# LPC18xx register map
File version: 18
Registers are 32-bit, read-write, reset 0x0 unless marked. A register's access mark holds for its fields unless they carry their own. Offsets are from the block's base; [hi:lo] are bit positions; {n}, {i} and the like mark numbered series; 'fields as' and 'values as' point back to an identical list.

## LCD — Product name title=UM10430 Chapter title=LPC18xx LCD Modification date=1/19/2011 Major revision=0 Minor revision=7
Base 0x40008000
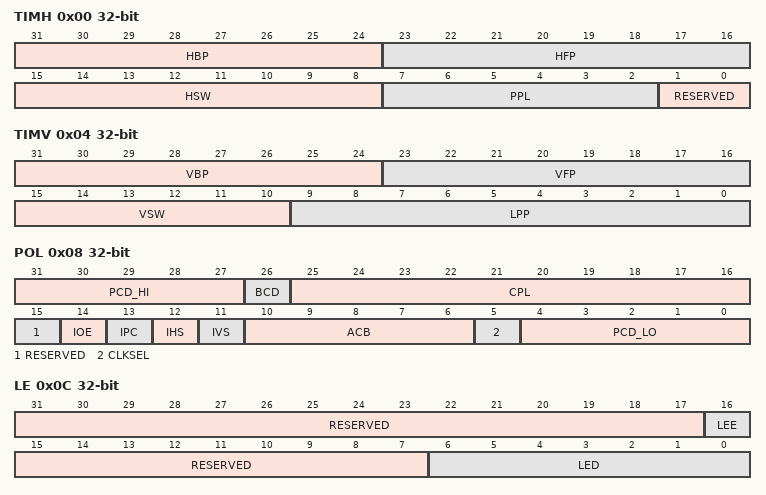
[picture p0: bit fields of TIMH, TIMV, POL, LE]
0x00 TIMH — Horizontal Timing Control register
  [31:24] HBP — Horizontal back porch. The 8-bit HBP field is used to specify the number of pixel clock periods inserted at the beginning of each line or row of pixels. After the line clock for the previous line has been deasserted, the value in HBP counts the number of pixel clocks to wait before starting the next display line. HBP can generate a delay of 1-256 pixel clock cycles. Program with desired value minus 1.
  [23:16] HFP — Horizontal front porch. The 8-bit HFP field sets the number of pixel clock intervals at the end of each line or row of pixels, before the LCD line clock is pulsed. When a complete line of pixels is transmitted to the LCD driver, the value in HFP counts the number of pixel clocks to wait before asserting the line clock. HFP can generate a period of 1-256 pixel clock cycles. Program with desired value minus 1.
  [15:8] HSW — Horizontal synchronization pulse width. The 8-bit HSW field specifies the pulse width of the line clock in passive mode, or the horizontal synchronization pulse in active mode. Program with desired value minus 1.
  [7:2] PPL — Pixels-per-line. The PPL bit field specifies the number of pixels in each line or row of the screen. PPL is a 6-bit value that represents between 16 and 1024 pixels per line. PPL counts the number of pixel clocks that occur before the HFP is applied. Program the value required divided by 16, minus 1. Actual pixels-per-line = 16 * (PPL + 1). For example, to obtain 320 pixels per line, program PPL as (320/16) -1 = 19.
  [1:0] RESERVED — Reserved, user software should not write ones to reserved bits. The value read from a reserved bit is not defined.
0x04 TIMV — Vertical Timing Control register
  [31:24] VBP — Vertical back porch. This is the number of inactive lines at the start of a frame, after the vertical synchronization period. The 8 bit VBP field specifies the number of line clocks inserted at the beginning of each frame. The VBP count starts immediately after the vertical synchronization signal for the previous frame has been negated for active mode, or the extra line clocks have been inserted as specified by the VSW bit field in passive mode. After this has occurred, the count value in VBP sets the number of line clock periods inserted before the next frame. VBP generates 0-255 extra line clock cycles. Program to zero on passive displays for improved contrast.
  [23:16] VFP — Vertical front porch. This is the number of inactive lines at the end of a frame, before the vertical synchronization period. The 8 bit VFP field specifies the number of line clocks to insert at the end of each frame. When a complete frame of pixels is transmitted to the LCD display, the value in VFP is used to count the number of line clock periods to wait. After the count has elapsed, the vertical synchronization signal, LCDFP, is asserted in active mode, or extra line clocks are inserted as specified by the VSW bit field in passive mode. VFP generates 0-255 line clock cycles. Program to zero on passive displays for improved contrast.
  [15:10] VSW — Vertical synchronization pulse width. This is the number of horizontal synchronization lines. The 6 bit VSW field specifies the pulse width of the vertical synchronization pulse. Program the register with the number of lines required, minus one. The number of horizontal synchronization lines must be small (for example, program to zero) for passive STN LCDs. The higher the value the worse the contrast on STN LCDs.
  [9:0] LPP — Lines per panel. This is the number of active lines per screen. The LPP field specifies the total number of lines or rows on the LCD panel being controlled. LPP is a 10 bit value allowing between 1 and 1024 lines. Program the register with the number of lines per LCD panel, minus 1. For dual panel displays, program the register with the number of lines on each of the upper and lower panels.
0x08 POL — Clock and Signal Polarity Control register
  [31:27] PCD_HI — Upper five bits of panel clock divisor. See description for PCD_LO, in bits [4:0] of this register.
  [26] BCD — Bypass pixel clock divider. Setting this to 1 bypasses the pixel clock divider logic. This is mainly used for TFT displays.
  [25:16] CPL — Clocks per line. This field specifies the number of actual LCDDCLK clocks to the LCD panel on each line. This is the number of PPL divided by either 1 (for TFT), 4 or 8 (for monochrome passive), 2 2/3 (for color passive), minus one. This must be correctly programmed in addition to the PPL bit in the TIMH register for the LCD display to work correctly.
  [15] RESERVED — Reserved, user software should not write ones to reserved bits. The value read from a reserved bit is not defined.
  [14] IOE — Invert output enable. This bit selects the active polarity of the output enable signal in TFT mode. In this mode, the LCDENAB pin is used as an enable that indicates to the LCD panel when valid display data is available. In active display mode, data is driven onto the LCD data lines at the programmed edge of LCDDCLK when LCDENAB is in its active state. 0 = LCDENAB output pin is active HIGH in TFT mode. 1 = LCDENAB output pin is active LOW in TFT mode.
  [13] IPC — Invert panel clock. The IPC bit selects the edge of the panel clock on which pixel data is driven out onto the LCD data lines. 0 = Data is driven on the LCD data lines on the rising edge of LCDDCLK. 1 = Data is driven on the LCD data lines on the falling edge of LCDDCLK.
  [12] IHS — Invert horizontal synchronization. The IHS bit inverts the polarity of the LCDLP signal. 0 = LCDLP pin is active HIGH and inactive LOW. 1 = LCDLP pin is active LOW and inactive HIGH.
  [11] IVS — Invert vertical synchronization. The IVS bit inverts the polarity of the LCDFP signal. 0 = LCDFP pin is active HIGH and inactive LOW. 1 = LCDFP pin is active LOW and inactive HIGH.
  [10:6] ACB — AC bias pin frequency. The AC bias pin frequency is only applicable to STN displays. These require the pixel voltage polarity to periodically reverse to prevent damage caused by DC charge accumulation. Program this field with the required value minus one to apply the number of line clocks between each toggle of the AC bias pin, LCDENAB. This field has no effect if the LCD is operating in TFT mode, when the LCDENAB pin is used as a data enable signal.
  [5] CLKSEL — Clock Select. This bit controls the selection of the source for LCDCLK. 0 = the clock source for the LCD block is CCLK. 1 = the clock source for the LCD block is LCDCLKIN (external clock input for the LVD).
  [4:0] PCD_LO — Lower five bits of panel clock divisor. The ten-bit PCD field, comprising PCD_HI (bits 31:27 of this register) and PCD_LO, is used to derive the LCD panel clock frequency LCDDCLK from the input clock, LCDDCLK = LCDCLK/(PCD+2). For monochrome STN displays with a 4 or 8-bit interface, the panel clock is a factor of four and eight down from the actual individual pixel clock rate. For color STN displays, 22/3 pixels are output per LCDDCLK cycle, so the panel clock is 0.375 times the pixel rate. For TFT displays, the pixel clock divider can be bypassed by setting the BCD bit in this register. Note: data path latency forces some restrictions on the usable minimum values for the panel clock divider in STN modes: Single panel color mode, PCD = 1 (LCDDCLK = LCDCLK/3). Dual panel color mode, PCD = 4 (LCDDCLK = LCDCLK/6). Single panel monochrome 4-bit interface mode, PCD = 2(LCDDCLK = LCDCLK/4). Dual panel monochrome 4-bit interface mode and single panel monochrome 8-bit interface mode, PCD = 6(LCDDCLK = LCDCLK/8). Dual panel monochrome 8-bit interface mode, PCD = 14(LCDDCLK = LCDCLK/16).
0x0C LE — Line End Control register
  [31:17] RESERVED — Reserved, user software should not write ones to reserved bits. The value read from a reserved bit is not defined.
  [16] LEE — LCD Line end enable. 0 = LCDLE disabled (held LOW). 1 = LCDLE signal active.
  [15:7] RESERVED — Reserved, user software should not write ones to reserved bits. The value read from a reserved bit is not defined.
  [6:0] LED — Line-end delay. Controls Line-end signal delay from the rising-edge of the last panel clock, LCDDCLK. Program with number of LCDCLK clock periods minus 1.
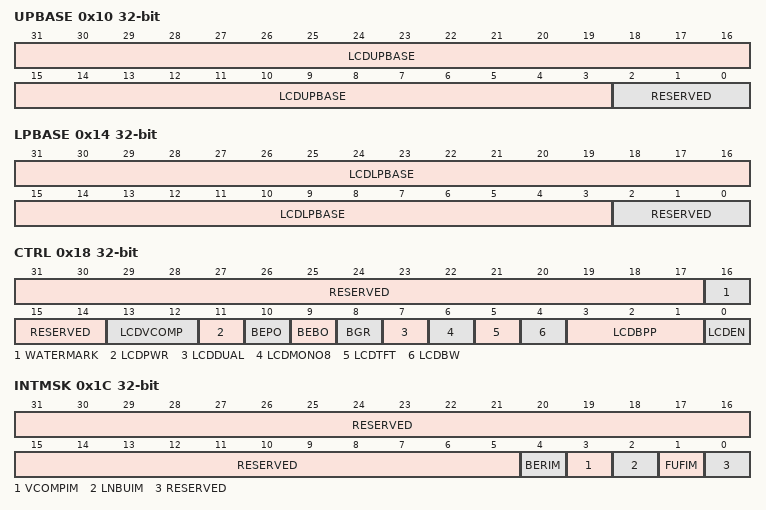
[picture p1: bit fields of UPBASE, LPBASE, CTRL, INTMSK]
0x10 UPBASE — Upper Panel Frame Base Address register
  [31:3] LCDUPBASE — LCD upper panel base address. This is the start address of the upper panel frame data in memory and is doubleword aligned.
  [2:0] RESERVED — Reserved, user software should not write ones to reserved bits. The value read from a reserved bit is not defined.
0x14 LPBASE — Lower Panel Frame Base Address register
  [31:3] LCDLPBASE — LCD lower panel base address. This is the start address of the lower panel frame data in memory and is doubleword aligned.
  [2:0] RESERVED — Reserved, user software should not write ones to reserved bits. The value read from a reserved bit is not defined.
0x18 CTRL — LCD Control register
  [31:17] RESERVED — Reserved, user software should not write ones to reserved bits. The value read from a reserved bit is not defined.
  [16] WATERMARK — LCD DMA FIFO watermark level. Controls when DMA requests are generated: 0 = An LCD DMA request is generated when either of the DMA FIFOs have four or more empty locations. 1 = An LCD DMA request is generated when either of the DMA FIFOs have eight or more empty locations.
  [15:14] RESERVED — Reserved, user software should not write ones to reserved bits. The value read from a reserved bit is not defined.
  [13:12] LCDVCOMP — LCD Vertical Compare Interrupt. Generate VComp interrupt at: 00 = start of vertical synchronization. 01 = start of back porch. 10 = start of active video. 11 = start of front porch.
  [11] LCDPWR — LCD power enable. 0 = power not gated through to LCD panel and LCDV[23:0] signals disabled, (held LOW). 1 = power gated through to LCD panel and LCDV[23:0] signals enabled, (active). See LCD power-up and power-down sequence for details on LCD power sequencing.
  [10] BEPO — Big-Endian Pixel Ordering. Controls pixel ordering within a byte: 0 = little-endian ordering within a byte. 1 = big-endian pixel ordering within a byte. The BEPO bit selects between little and big-endian pixel packing for 1, 2, and 4 bpp display modes, it has no effect on 8 or 16 bpp pixel formats. See Pixel serializer for more information on the data format.
  [9] BEBO — Big-endian Byte Order. Controls byte ordering in memory: 0 = little-endian byte order. 1 = big-endian byte order.
  [8] BGR — Color format selection. 0 = RGB: normal output. 1 = BGR: red and blue swapped.
  [7] LCDDUAL — Single or Dual LCD panel selection. STN LCD interface is: 0 = single-panel. 1 = dual-panel.
  [6] LCDMONO8 — Monochrome LCD interface width. This bit controls whether a monochrome STN LCD uses a 4 or 8-bit parallel interface. It has no meaning in other modes and must be programmed to zero. 0 = monochrome LCD uses a 4-bit interface. 1 = monochrome LCD uses a 8-bit interface.
  [5] LCDTFT — LCD panel TFT type selection. 0 = LCD is an STN display. Use gray scaler. 1 = LCD is a TFT display. Do not use gray scaler.
  [4] LCDBW — STN LCD monochrome/color selection. 0 = STN LCD is color. 1 = STN LCD is monochrome. This bit has no meaning in TFT mode.
  [3:1] LCDBPP — LCD bits per pixel: Selects the number of bits per LCD pixel: 000 = 1 bpp. 001 = 2 bpp. 010 = 4 bpp. 011 = 8 bpp. 100 = 16 bpp. 101 = 24 bpp (TFT panel only). 110 = 16 bpp, 5:6:5 mode. 111 = 12 bpp, 4:4:4 mode.
  [0] LCDEN — LCD enable control bit. 0 = LCD disabled. Signals LCDLP, LCDDCLK, LCDFP, LCDENAB, and LCDLE are low. 1 = LCD enabled. Signals LCDLP, LCDDCLK, LCDFP, LCDENAB, and LCDLE are high. See LCD power-up and power-down sequence for details on LCD power sequencing.
0x1C INTMSK — Interrupt Mask register
  [31:5] RESERVED — Reserved, user software should not write ones to reserved bits. The value read from a reserved bit is not defined.
  [4] BERIM — AHB master error interrupt enable. 0: The AHB Master error interrupt is disabled. 1: Interrupt will be generated when an AHB Master error occurs.
  [3] VCOMPIM — Vertical compare interrupt enable. 0: The vertical compare time interrupt is disabled. 1: Interrupt will be generated when the vertical compare time (as defined by LcdVComp field in the CTRL register) is reached.
  [2] LNBUIM — LCD next base address update interrupt enable. 0: The base address update interrupt is disabled. 1: Interrupt will be generated when the LCD base address registers have been updated from the next address registers.
  [1] FUFIM — FIFO underflow interrupt enable. 0: The FIFO underflow interrupt is disabled. 1: Interrupt will be generated when the FIFO underflows.
  [0] RESERVED — Reserved, user software should not write ones to reserved bits. The value read from a reserved bit is not defined.
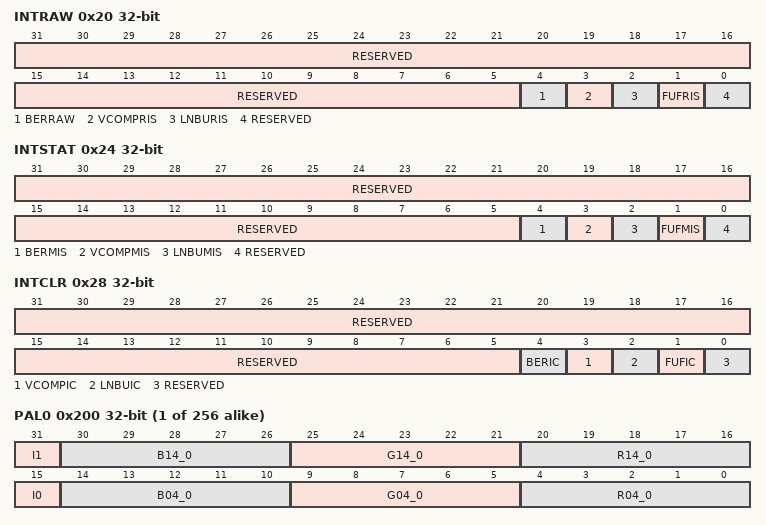
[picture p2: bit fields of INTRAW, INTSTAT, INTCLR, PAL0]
0x20 INTRAW ro — Raw Interrupt Status register
  [31:5] RESERVED — Reserved, user software should not write ones to reserved bits. The value read from a reserved bit is not defined.
  [4] BERRAW — AHB master bus error raw interrupt status. Set when the AHB master interface receives a bus error response from a slave. Generates an interrupt if the BERIM bit in the INTMSK register is set.
  [3] VCOMPRIS — Vertical compare raw interrupt status. Set when one of the four vertical regions is reached, as selected by the LcdVComp bits in the CTRL register. Generates an interrupt if the VCompIM bit in the INTMSK register is set.
  [2] LNBURIS — LCD next address base update raw interrupt status. Mode dependent. Set when the current base address registers have been successfully updated by the next address registers. Signifies that a new next address can be loaded if double buffering is in use. Generates an interrupt if the LNBUIM bit in the INTMSK register is set.
  [1] FUFRIS — FIFO underflow raw interrupt status. Set when either the upper or lower DMA FIFOs have been read accessed when empty causing an underflow condition to occur. Generates an interrupt if the FUFIM bit in the INTMSK register is set.
  [0] RESERVED — Reserved, user software should not write ones to reserved bits. The value read from a reserved bit is not defined.
0x24 INTSTAT ro — Masked Interrupt Status register
  [31:5] RESERVED — Reserved, user software should not write ones to reserved bits. The value read from a reserved bit is not defined.
  [4] BERMIS — AHB master bus error masked interrupt status. Set when the both the BERRAW bit in the INTRAW register and the BERIM bit in the INTMSK register are set.
  [3] VCOMPMIS — Vertical compare masked interrupt status. Set when the both the VCompRIS bit in the INTRAW register and the VCompIM bit in the INTMSK register are set.
  [2] LNBUMIS — LCD next address base update masked interrupt status. Set when the both the LNBURIS bit in the INTRAW register and the LNBUIM bit in the INTMSK register are set.
  [1] FUFMIS — FIFO underflow masked interrupt status. Set when the both the FUFRIS bit in the INTRAW register and the FUFIM bit in the INTMSK register are set.
  [0] RESERVED — Reserved, user software should not write ones to reserved bits. The value read from a reserved bit is not defined.
0x28 INTCLR wo — Interrupt Clear register
  [31:5] RESERVED — Reserved, user software should not write ones to reserved bits. The value read from a reserved bit is not defined.
  [4] BERIC — AHB master error interrupt clear. Writing a 1 to this bit clears the AHB master error interrupt.
  [3] VCOMPIC — Vertical compare interrupt clear. Writing a 1 to this bit clears the vertical compare interrupt.
  [2] LNBUIC — LCD next address base update interrupt clear. Writing a 1 to this bit clears the LCD next address base update interrupt.
  [1] FUFIC — FIFO underflow interrupt clear. Writing a 1 to this bit clears the FIFO underflow interrupt.
  [0] RESERVED — Reserved, user software should not write ones to reserved bits. The value read from a reserved bit is not defined.
0x2C UPCURR ro — Upper Panel Current Address Value register
  [31:0] LCDUPCURR — LCD Upper Panel Current Address. Contains the current LCD upper panel data DMA address.
0x30 LPCURR ro — Lower Panel Current Address Value register
  [31:0] LCDLPCURR — LCD Lower Panel Current Address. Contains the current LCD lower panel data DMA address.
{0x200+4i} PAL{i} (i=0..255) — 256x16-bit Color Palette registers
  [31] I1 — Intensity / unused bit. Can be used as the LSB of the R, G, and B inputs to a 6:6:6 TFT display, doubling the number of colors to 64K, where each color has two different intensities.
  [30:26] B14_0 — Blue palette data.
  [25:21] G14_0 — Green palette data.
  [20:16] R14_0 — Red palette data. For STN displays, only the four MSBs, bits [4:1], are used. For monochrome displays only the red palette data is used. All of the palette registers have the same bit fields.
  [15] I0 — Intensity / unused bit. Can be used as the LSB of the R, G, and B inputs to a 6:6:6 TFT display, doubling the number of colors to 64K, where each color has two different intensities.
  [14:10] B04_0 — Blue palette data.
  [9:5] G04_0 — Green palette data.
  [4:0] R04_0 — Red palette data. For STN displays, only the four MSBs, bits [4:1], are used. For monochrome displays only the red palette data is used. All of the palette registers have the same bit fields.
{0x800+4i} CRSR_IMG{i} (i=0..255) — Cursor Image registers
  [31:0] CRSR_IMG — Cursor Image data. The 256 words of the cursor image registers define the appearance of either one 64x64 cursor or 4 32x32 cursors.
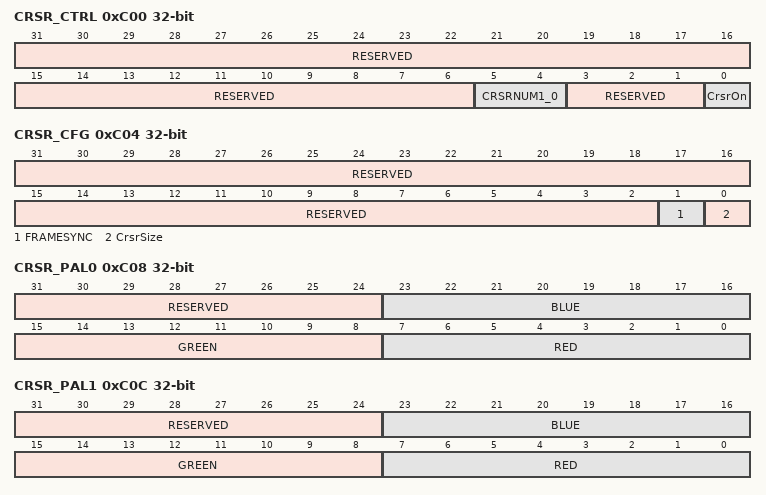
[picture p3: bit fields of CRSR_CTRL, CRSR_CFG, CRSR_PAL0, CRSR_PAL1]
0xC00 CRSR_CTRL — Cursor Control register
  [31:6] RESERVED — Reserved, user software should not write ones to reserved bits. The value read from a reserved bit is not defined.
  [5:4] CRSRNUM1_0 — Cursor image number. If the selected cursor size is 6x64, this field has no effect. If the selected cursor size is 32x32: 00 = Cursor0. 01 = Cursor1. 10 = Cursor2. 11 = Cursor3.
  [3:1] RESERVED — Reserved, user software should not write ones to reserved bits. The value read from a reserved bit is not defined.
  [0] CrsrOn — Cursor enable. 0 = Cursor is not displayed. 1 = Cursor is displayed.
0xC04 CRSR_CFG — Cursor Configuration register
  [31:2] RESERVED — Reserved, user software should not write ones to reserved bits. The value read from a reserved bit is not defined.
  [1] FRAMESYNC — Cursor frame synchronization type. 0 = Cursor coordinates are asynchronous. 1 = Cursor coordinates are synchronized to the frame synchronization pulse.
  [0] CrsrSize — Cursor size selection. 0 = 32x32 pixel cursor. Allows for 4 defined cursors. 1 = 64x64 pixel cursor.
0xC08 CRSR_PAL0 — Cursor Palette register 0
  [31:24] RESERVED — Reserved, user software should not write ones to reserved bits. The value read from a reserved bit is not defined.
  [23:16] BLUE — Blue color component.
  [15:8] GREEN — Green color component
  [7:0] RED — Red color component
0xC0C CRSR_PAL1 — Cursor Palette register 1
  fields as CRSR_PAL0
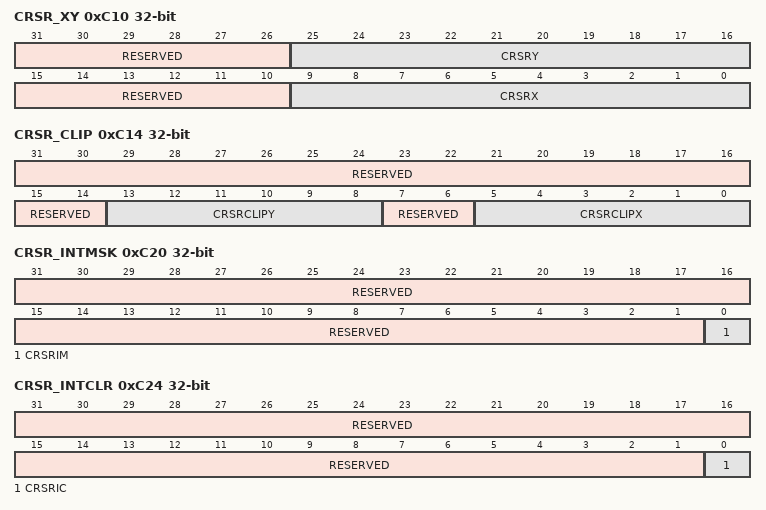
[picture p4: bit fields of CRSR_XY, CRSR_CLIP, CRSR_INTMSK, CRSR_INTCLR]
0xC10 CRSR_XY — Cursor XY Position register
  [31:26] RESERVED — Reserved, user software should not write ones to reserved bits. The value read from a reserved bit is not defined.
  [25:16] CRSRY — Y ordinate of the cursor origin measured in pixels. When 0, the top edge of the cursor is at the top of the display.
  [15:10] RESERVED — Reserved, user software should not write ones to reserved bits. The value read from a reserved bit is not defined.
  [9:0] CRSRX — X ordinate of the cursor origin measured in pixels. When 0, the left edge of the cursor is at the left of the display.
0xC14 CRSR_CLIP — Cursor Clip Position register
  [31:14] RESERVED — Reserved, user software should not write ones to reserved bits. The value read from a reserved bit is not defined.
  [13:8] CRSRCLIPY — Cursor clip position for Y direction. Distance from the top of the cursor image to the first displayed pixel in the cursor. When 0, the first displayed pixel is from the top line of the cursor image.
  [7:6] RESERVED — Reserved, user software should not write ones to reserved bits. The value read from a reserved bit is not defined.
  [5:0] CRSRCLIPX — Cursor clip position for X direction. Distance from the left edge of the cursor image to the first displayed pixel in the cursor. When 0, the first pixel of the cursor line is displayed.
0xC20 CRSR_INTMSK — Cursor Interrupt Mask register
  [31:1] RESERVED — Reserved, user software should not write ones to reserved bits. The value read from a reserved bit is not defined.
  [0] CRSRIM — Cursor interrupt mask. When clear, the cursor never interrupts the processor. When set, the cursor interrupts the processor immediately after reading of the last word of cursor image.
0xC24 CRSR_INTCLR wo — Cursor Interrupt Clear register
  [31:1] RESERVED — Reserved, user software should not write ones to reserved bits. The value read from a reserved bit is not defined.
  [0] CRSRIC — Cursor interrupt clear. Writing a 0 to this bit has no effect. Writing a 1 to this bit causes the cursor interrupt status to be cleared.
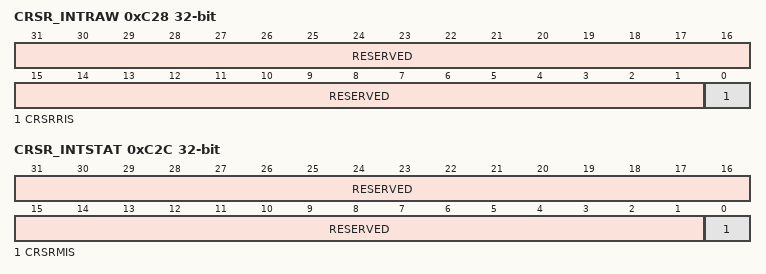
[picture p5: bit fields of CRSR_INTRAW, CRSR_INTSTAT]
0xC28 CRSR_INTRAW ro — Cursor Raw Interrupt Status register
  [31:1] RESERVED — Reserved, user software should not write ones to reserved bits. The value read from a reserved bit is not defined.
  [0] CRSRRIS — Cursor raw interrupt status. The cursor interrupt status is set immediately after the last data is read from the cursor image for the current frame. This bit is cleared by writing to the CrsrIC bit in the CRSR_INTCLR register.
0xC2C CRSR_INTSTAT ro — Cursor Masked Interrupt Status register
  [31:1] RESERVED — Reserved, user software should not write ones to reserved bits. The value read from a reserved bit is not defined.
  [0] CRSRMIS — Cursor masked interrupt status. The cursor interrupt status is set immediately after the last data read from the cursor image for the current frame, providing that the corresponding bit in the CRSR_INTMSK register is set. The bit remains clear if the CRSR_INTMSK register is clear. This bit is cleared by writing to the CRSR_INTCLR register.
